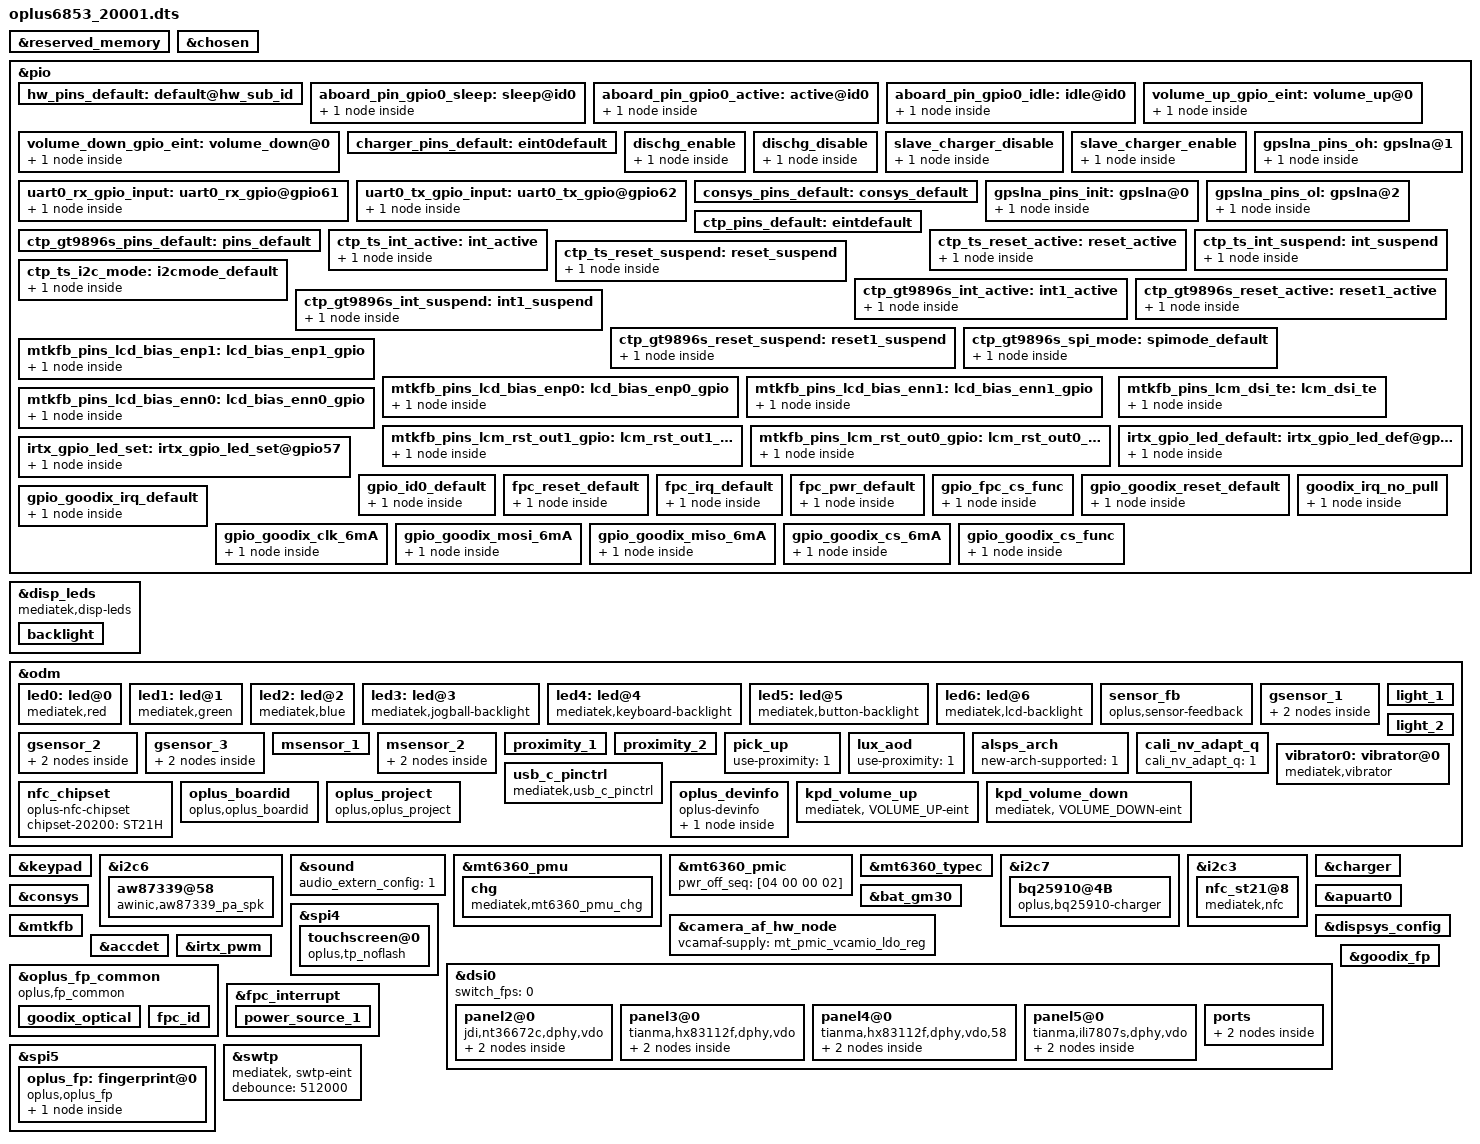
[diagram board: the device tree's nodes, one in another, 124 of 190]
/*
 * Mediatek's mt6853 SoC device tree source
 *
 * Copyright (C) 2016 MediaTek Inc.
 *
 * This program is free software; you can redistribute it and/or modify
 * it under the terms of the GNU General Public License version 2 as
 * published by the Free Software Foundation.
 *
 * This program is distributed in the hope that it will be useful,
 * but WITHOUT ANY WARRANTY; without even the implied warranty of
 * MERCHANTABILITY or FITNESS FOR A PARTICULAR PURPOSE.
 * See http://www.gnu.org/licenses/gpl-2.0.html for more details.
 */
/dts-v1/;
/plugin/;
#include <dt-bindings/interrupt-controller/irq.h>
#include <dt-bindings/interrupt-controller/arm-gic.h>
#include <dt-bindings/pinctrl/mt6853-pinfunc.h>

&reserved_memory {
};

/* chosen */
&chosen {

	atag,videolfb-fb_base_l = <0x7e605000>;
	atag,videolfb-fb_base_h = <0x0>;
	atag,videolfb-islcmfound = <1>;
	atag,videolfb-islcm_inited = <0>;
	atag,videolfb-fps= <6000>;
	atag,videolfb-vramSize= <0x1be0000>;
	atag,videolfb-lcmname=
		"nt35595_fhd_dsi_cmd_truly_nt50358_drv";
};
&pio {
        hw_pins_default:default@hw_sub_id {
        };

        aboard_pin_gpio0_sleep:sleep@id0 {
                pins_cmd_dat {
                        pinmux = <PINMUX_GPIO91__FUNC_GPIO91>;
                        slew-rate = <0>;
                        bias-pull-down;
                        input-enable;
                };
        };

        aboard_pin_gpio0_active:active@id0 {
                pins_cmd_dat {
                        pinmux = <PINMUX_GPIO91__FUNC_GPIO91>;
                        slew-rate = <0>;
                        bias-pull-up;
                        input-enable;
                };
        };

        aboard_pin_gpio0_idle:idle@id0 {
                pins_cmd_dat {
                        pinmux = <PINMUX_GPIO91__FUNC_GPIO91>;
                        slew-rate = <0>;
                        bias-disable;
                        input-enable;
                };
        };
};

&disp_leds {
	compatible = "mediatek,disp-leds";
	backlight {
		label = "lcd-backlight";
		max-brightness = <4095>;
		led-bits = <12>;
		trans-bits = <12>;
		default-state = "on";
	};
};

&odm {
	led0:led@0 {
		compatible = "mediatek,red";
		led_mode = <0>;
		data = <1>;
		pwm_config = <0 0 0 0 0>;
	};
	led1:led@1 {
		compatible = "mediatek,green";
		led_mode = <0>;
		data = <1>;
		pwm_config = <0 0 0 0 0>;
	};
	led2:led@2 {
		compatible = "mediatek,blue";
		led_mode = <0>;
		data = <1>;
		pwm_config = <0 0 0 0 0>;
	};
	led3:led@3 {
		compatible = "mediatek,jogball-backlight";
		led_mode = <0>;
		data = <1>;
		pwm_config = <0 0 0 0 0>;
	};
	led4:led@4 {
		compatible = "mediatek,keyboard-backlight";
		led_mode = <0>;
		data = <1>;
		pwm_config = <0 0 0 0 0>;
	};
	led5:led@5 {
		compatible = "mediatek,button-backlight";
		led_mode = <0>;
		data = <1>;
		pwm_config = <0 0 0 0 0>;
	};
	led6:led@6 {
		compatible = "mediatek,lcd-backlight";
		led_mode = <4>;
		data = <1>;
		pwm_config = <0 1 0 0 0>;
	};

	sensor_fb: sensor_fb {
		compatible = "oplus,sensor-feedback";
	};

	/*
	enum {
		LIS3DH,
		LSM6DS3,
		BMI160,
		LIS2HH12,
		LSM6DSM,
		BMI2XY,
		LSM6DSO,
		ICM4X6XX,
	};
	*/
	gsensor_1: gsensor_1 {
		status = "okay";
		sensor_name = <6>;//LSM6DSO
		i2c_num = <2>;
		i2c_addr = <0>;
		direction = <7>;
		eint_num = <3>;
		para_num = <2>;
		step_count_7_en = <0>;
		config_miso = <0>;
		correct_y_bias = <0>;
		cali_nv_adapt_q_flag = <1>; // just for oplus MTK5G q projects
		gsensor_para_1 {
			match_projects = <20001 20002 20003>;
			direction_adpt = <0 7 0 7 0 7 0 7>;
		};
		gsensor_para_2 {
			match_projects = <20200>;
			direction_adpt = <2 5 4 5 5 5 6 5>;
		};
	};

	gsensor_2: gsensor_2 {
		status = "okay";
		sensor_name = <4>;//LSM6DSM
		i2c_num = <2>;
		i2c_addr = <0>;
		direction = <7>;
		eint_num = <3>;
		para_num = <2>;
		step_count_7_en = <0>;
		config_miso = <0>;
		correct_y_bias = <0>;
		cali_nv_adapt_q_flag = <1>; // just for oplus MTK5G q projects
		gsensor_para_1 {
			match_projects = <20001 20002 20003>;
			direction_adpt = <0 7 0 7 0 7 0 7>;
		};
		gsensor_para_2 {
			match_projects = <20200>;
			direction_adpt = <2 5 4 5 5 5 6 5>;
		};
	};

	gsensor_3: gsensor_3 {
		status = "okay";
		sensor_name = <2>;//BMI160
		i2c_num = <2>;
		i2c_addr = <0>;
		direction = <4>;
		eint_num = <3>;
		step_count_7_en = <1>;
		config_miso = <0>;
		correct_y_bias = <0>;
		para_num = <2>;
		cali_nv_adapt_q_flag = <1>; // just for oplus MTK5G q projects
		gsensor_para_1 {
			match_projects = <20001 20002 20003>;
			direction_adpt = <0 4 0 4 0 4 0 4>;
		};
		gsensor_para_2 {
			match_projects = <20200>;
			direction_adpt = <2 6 4 6 5 6 6 6>;
		};
	};

	/*
	enum {
		AKM09911,
		MMC3530,
		MMC5603,
		MXG4300,
	};
	*/
	msensor_1: msensor_1 {
		status = "okay";
		sensor_name = <0>;//AKM09911
		i2c_num = <0>;
		i2c_addr = <12>;
		direction = <3>;
		eint_num = <0>;
		parameter-number= <18>;
		soft-mag-parameter = <9454 0 5 1 54 1 5 1 10343 0 143 1 54 1 143 1 10231 0>;
	};
	msensor_2: msensor_2 {
		status = "okay";
		sensor_name = <2>;//MMC5603
		i2c_num = <0>;
		i2c_addr = <48>;
		direction = <3>;
		eint_num = <0>;
		parameter-number= <18>;
		//soft-mag-parameter = <9997 0 37 0 243 1 21 0 10654 0 11 0 868 0 516 1 11372 0>;
		para_num = <2>;
		mag_para_1 {
			match_projects = <20001 20002 20003>;
			soft-mag-parameter = <9997 0 37 0 243 1 21 0 10654 0 11 0 868 0 516 1 11372 0>;
		};
		mag_para_2 {
			match_projects = <20200>;
			soft-mag-parameter = <9566 0 2898 0 290 0 801 0 13224 0 159 1 2426 0 1755 1 12524 0>;
		};
	};
	/*
	enum {
		TMD2725,
		APSD9922,
		STK3335,
		STK3331,
		STK2232,
		TCS3701,
		STK32600,
		STK33502,
		MN78911,
	};
	*/
	proximity_1: proximity_1 {
		status = "okay";
		sensor_name = <7>;//STK33502
		i2c_num = <0>;
		i2c_addr = <70>;
		direction = <4>;
		eint_num = <11>;
		low_step = <300>;
		high_step = <400>;
		low_limit = <400>;
		high_limit = <600>;
		dirty_low_step = <100>;
		dirty_high_step = <150>;
		ps_dirty_limit = <1023>;
		ps_ir_limit = <500>;
		ps_adjust_min = <0>;
		ps_adjust_max = <600>;
		sampling_count = <5>;
		step_max = <400>;
		step_min = <100>;
		step_div = <1500>;
		anti_shake_delta = <80>;
		dynamic_cali_max = <2000>;
		raw2offset_radio = <1000>;
		offset_max = <60000>;
		offset_range_min = <0>;
		offset_range_max = <65534>;
		force_cali_limit = <2000>;
		cali_jitter_limit = <30>;
		cal_offset_margin = <3000>;
		sensor-reg = <0x01 0x33 0x03 0x60>; //according to q, we got 100ma & 800us
	};
	proximity_2: proximity_2 {
		status = "okay";
		sensor_name = <8>;//MN78911
		i2c_num = <0>;
		i2c_addr = <0x41>;
		direction = <4>;
		eint_num = <11>;
		low_step = <300>;
		high_step = <400>;
		low_limit = <400>;
		high_limit = <600>;
		dirty_low_step = <100>;
		dirty_high_step = <150>;
		ps_dirty_limit = <1023>;
		ps_ir_limit = <500>;
		ps_adjust_min = <0>;
		ps_adjust_max = <600>;
		sampling_count = <5>;
		step_max = <400>;
		step_min = <110>;
		step_div = <1500>;
		anti_shake_delta = <80>;
		dynamic_cali_max = <2000>;
		raw2offset_radio = <1000>;
		offset_max = <60000>;
		offset_range_min = <0>;
		offset_range_max = <65534>;
		force_cali_limit = <2000>;
		cali_jitter_limit = <30>;
		cal_offset_margin = <3000>;
	};
	light_1: light_1 {
		status = "okay";
		sensor_name = <7>;//STK33502
		i2c_num = <0>;
		i2c_addr = <70>;
		direction = <4>;
		eint_num = <11>;
		als_buffer_length =<4>;
		als_type = <1>;//<1-normal;2-under screen;3-normal needed compensation>
		als_ratio = <110>;
		device_name = "stk33502";
	};
	/* 20001 not using
	als_radio_lcd:als_radio_lcd {
		status = "okay";
		jdi_als_radio = <110>;
		tianma_als_radio = <90>;
	};
	*/
	light_2: light_2 {
		status = "okay";
		sensor_name = <8>;//MN78911
		i2c_num = <0>;
		i2c_addr = <0x41>;
		direction = <4>;
		eint_num = <11>;
		als_buffer_length = <10>;
		als_ratio = <110>;
		als_type = <1>;
		device_name = "mn78911";
	};
	pick_up: pick_up {
		status = "okay";
		use-proximity = <1>;
	};
	lux_aod: lux_aod {
		status = "okay";
		use-proximity = <1>;
	};
	alsps_arch: alsps_arch {
		status = "okay";
		new-arch-supported = <1>;
	};
	cali_nv_adapt_q: cali_nv_adapt_q {
		status = "okay";
		cali_nv_adapt_q = <1>;
	};
	vibrator0:vibrator@0 {
		compatible = "mediatek,vibrator";
		//#ifdef OPLUS_ARCH_EXTENDS
		vib_timer = <30>;
		vib_limit = <0>;
		//#else
		//vib_timer = <25>;
		//vib_limit = <9>;
		//#endif /* OPLUS_ARCH_EXTENDS */
		//#ifdef OPLUS_ARCH_EXTENDS
		vib_vol= <11>;
		//#endif /* OPLUS_ARCH_EXTENDS */
	};
	usb_c_pinctrl:usb_c_pinctrl {
		compatible = "mediatek,usb_c_pinctrl";
	};

//#ifdef OPLUS_FEATURE_CONNFCSOFT
	nfc_chipset {
		compatible = "oplus-nfc-chipset";
		chipset-20200 = "ST21H";
	};
//#endif /* OPLUS_FEATURE_CONNFCSOFT */

	oplus_boardid:oplus_boardid {
		compatible = "oplus,oplus_boardid";
		oplus_boardid,dtsino="20001";//only one u32
		oplus_boardid,pcbmask="0xffff";//all mask 0xffff
	};
	oplus_project:oplus_project {
		compatible = "oplus,oplus_project";
	};
	oplus_devinfo:oplus_devinfo {
		compatible = "oplus-devinfo";
		pinctrl-names = "default", "aboard_gpio0_sleep", "aboard_gpio0_active";
		pinctrl-0 = <&hw_pins_default>;
		pinctrl-1 = <&aboard_pin_gpio0_sleep>;
		pinctrl-2 = <&aboard_pin_gpio0_active>;
		main-sub {
			compatible = "hw-match, main-sub";
			aboard-gpio0 = <&pio 91 0x00>;
			aboard-patterns = <1 1 1 0>;
			/*main board*/
			match-projects = <20001 20002 20003 20200>;
		};
	};
/*OPLUS_FEAUTRE_KEYPAD keypad start*/
	kpd_volume_up:kpd_volume_up {
		compatible = "mediatek, VOLUME_UP-eint";
		interrupt-parent = <&pio>;
		interrupts = <1 IRQ_TYPE_EDGE_FALLING 1 0>;
		debounce = <32000>;
		status = "okay";
	};

	kpd_volume_down:kpd_volume_down {
		compatible = "mediatek, VOLUME_DOWN-eint";
		interrupt-parent = <&pio>;
		interrupts = <80 IRQ_TYPE_EDGE_FALLING 80 0>;
		debounce = <32000>;
		status = "okay";
	};
/*OPLUS_FEAUTRE_KEYPAD keypad end*/
};
/*OPLUS_FEAUTRE_KEYPAD keypad start*/
&keypad {
	keypad,volume-up	= <&pio 1 0x00>;
	keypad,volume-down	= <&pio 80 0x00>;
	pinctrl-names = "volume_up_as_int", "volume_down_as_int";
	pinctrl-0 = <&volume_up_gpio_eint>;
	pinctrl-1 = <&volume_down_gpio_eint>;
	status = "okay";
};
&pio {
	volume_up_gpio_eint:volume_up@0{
		pins_cmd_dat {
			pinmux = <PINMUX_GPIO1__FUNC_GPIO1>;
			slew-rate = <0>;  /*direction 0:in, 1:out*/
			input-enable;
		};
	};

	volume_down_gpio_eint:volume_down@0{
		pins_cmd_dat {
			pinmux = <PINMUX_GPIO80__FUNC_GPIO80>;
			slew-rate = <0>;  /*direction 0:in, 1:out*/
			input-enable;
		};
	};
};
/*OPLUS_FEAUTRE_KEYPAD keypad end*/

/*OPLUS_ARCH_EXTENDS*/
&i2c6 {
    #address-cells = <1>;
    #size-cells = <0>;

    aw87339@58 {
        compatible = "awinic,aw87339_pa_spk";
        reg = <0x58>;
        //reset-gpio = <&tlmm 114 0x01>;
        reset-gpio = <&pio 139 0>;
        status = "okay";
    };
};
/*OPLUS_ARCH_EXTENDS*/
&sound {
	/* this dtsi config for product's special config, AudioHal read ctl 'OPLUS_AUDIO_EXTERN_CONFIG' get the values*
	 * 1st value --> PA type: 0:NXP Pa, 1:Awinic Pa */
	audio_extern_config = <1>;
};
//#endif /* OPLUS_ARCH_EXTENDS */
/* Charging Start */

&mt6360_pmu {
	mt6360,intr_gpio_num = <10>; /* direct defined GPIO num */
	mt6360,intr_gpio = <&pio 10 0x0>;
	disable_lpsd = <1>;
};

&mt6360_pmic {
	pwr_off_seq = [04 00 00 02];
};

&mt6360_typec {
	mt6360pd,intr_gpio_num = <9>; /* direct defined GPIO num */
	mt6360pd,intr_gpio = <&pio 9 0x0>;
	//mt6360pd,pcb_gpio = <&pio 57 0x0>;
	//mt6360pd,pcb_gpio_num = <57>;
};

&mt6360_pmu {
	chg {
		compatible = "mediatek,mt6360_pmu_chg";
		interrupt-parent = <&mt6360_pmu>;
		interrupts = <4 0>, <6 0>, <7 0>, <9 0>,
				<12 0>, <13 0>, <14 0>, <15 0>,
				<27 0>, <29 0>, <30 0>, <32 0>,
				<35 0>, <40 0>, <48 0>, <60 0>,
				<53 0>;
		interrupt-names = "chg_treg_evt", "chg_mivr_evt",
				"pwr_rdy_evt", "chg_batsysuv_evt",
				"chg_vsysuv_evt", "chg_vsysov_evt",
				"chg_vbatov_evt", "chg_vbusov_evt",
				"chg_tmri", "chg_adpbadi",
				"chg_rvpi",  "chg_aiccmeasl",
				"wdtmri", "pumpx_donei",
				"attachi", "chrdet_ext_evt",
				"hvdcp_det";
		io-channels = <&adc 0>, <&adc 1>, <&adc 3>, <&adc 4>,
				<&adc 5>, <&adc 6>, <&adc 8>, <&adc 10>;
		io-channel-names = "USBID", "VBUSDIV5", "VSYS", "VBAT",
				"IBUS", "IBAT", "TEMP_JC", "TS";
		chg_name = "primary_chg";
		ichg = <2000000>;               /* uA */
		aicr = <500000>;                /* uA */
		mivr = <4400000>;               /* uV */
		cv = <4350000>;                 /* uA */
		ieoc = <150000>;                /* uA */
		safety_timer = <12>;            /* hour */
		ircmp_resistor = <25000>;       /* uohm */
		ircmp_vclamp = <32000>;         /* uV */
		en_te = <1>;
		en_wdt = <1>;
		aicc_once = <1>;
		post_aicc = <1>;
		batoc_notify = <0>;
	};
};


&i2c7 {
	bq25910@4B{
		status = "okay";
		compatible = "oplus,bq25910-charger";
		reg = <0x4B>;
		chip-name = "BQ25910";

		pinctrl-names = "slave_charger_disable", "slave_charger_enable";
		pinctrl-0 = <&slave_charger_disable>;
		pinctrl-1 = <&slave_charger_enable>;

		qcom,slave-chg-en-gpio = <&pio 140 0x00>;
	};
};

//#ifdef OPLUS_FEATURE_NFC_BRINGUP
//Add for:NFC ST device
&i2c3 {
       status = "okay";
       nfc_st21@8 {
           compatible ="mediatek,nfc";
           reg = <0x8>;
           gpio-irq-std    = <&pio 5 0x0>;
           gpio-rst-std    = <&pio 11 0x0>;
           gpio-clkreq-std = <&pio 81 0x0>;
       };
};
//#endif /* OPLUS_FEATURE_NFC_BRINGUP */

&charger {
	io-channels =  <&auxadc 3>,<&auxadc 4>,
		<&auxadc 5>;
	io-channel-names = "auxadc3-chargeric_temp","auxadc4-usb_temp_v_l",
		"auxadc5-usb_temp_v_r";

	pinctrl-names = "default", "dischg_enable", "dischg_disable";
	pinctrl-0 = <&charger_pins_default>;
	pinctrl-1 = <&dischg_enable>;
	pinctrl-2 = <&dischg_disable>;

	//for oplus chg framework:
	qcom,input_current_charger_ma = <2000>;
        qcom,input_current_usb_ma = <500>;
        qcom,input_current_cdp_ma = <1500>;
        qcom,input_current_led_ma = <1200>;
        qcom,input_current_led_ma_high = <1000>;
        qcom,input_current_led_ma_warm = <1500>;
        qcom,input_current_led_ma_normal = <2000>;
        qcom,input_current_led_ma_forcmcc = <500>;
        qcom,input_current_camera_ma = <2000>;
        qcom,input_current_calling_ma = <1500>;
        qcom,qc_input_current_charger_ma = <2000>;

	qcom,iterm_disabled = <0>;
	qcom,iterm_ma = <200>;
	qcom,recharge-mv = <100>;

	qcom,batt_capacity_mah = <3945>;

	qcom,removed_bat_decidegc = <190>;  /* < -19C */

	qcom,cold_bat_decidegc = <20>;  /* -2C ~ 0C */
        qcom,temp_cold_vfloat_mv = <3980>;
        qcom,temp_cold_fastchg_current_ma = <300>;

        qcom,little_cold_bat_decidegc = <0>;    /* 0C ~ 5C */
        qcom,temp_little_cold_vfloat_mv = <4385>;
        qcom,temp_little_cold_fastchg_current_ma_high = <550>;
        qcom,temp_little_cold_fastchg_current_ma_low = <550>;
        qcom,temp_little_cold_fastchg_current_ma = <550>;
        qcom,qc_temp_little_cold_fastchg_current_ma_high = <1850>;
        qcom,qc_temp_little_cold_fastchg_current_ma_low = <1100>;

	qcom,cool_bat_decidegc = <50>;  /* 5C ~ 12C */
        qcom,temp_cool_vfloat_mv = <4385>;
        qcom,temp_cool_fastchg_current_ma_high = <1100>;
        qcom,temp_cool_fastchg_current_ma_low = <500>;
        qcom,qc_temp_cool_fastchg_current_ma_high = <3400>;
        qcom,qc_temp_cool_fastchg_current_ma_low = <2600>;

        qcom,little_cool_bat_decidegc = <120>;  /* 12C ~ 16C */
        qcom,temp_little_cool_vfloat_mv = <4385>;
        qcom,temp_little_cool_fastchg_current_ma = <1650>;
        qcom,temp_little_cool_fastchg_current_ma_high = <1650>;
	qcom,temp_little_cool_fastchg_current_ma_low = <1650>;
	qcom,qc_temp_little_cool_fastchg_current_ma = <3400>;

        qcom,normal_bat_decidegc = <160>;       /* 16C ~ 45C */
        qcom,temp_normal_fastchg_current_ma = <2600>;
        qcom,temp_normal_vfloat_mv = <4385>;
        qcom,qc_temp_normal_fastchg_current_ma = <2600>;

        qcom,normal_phase1_bat_decidegc = <160>;       /* 16C ~ 22C */
        qcom,temp_normal_phase1_vfloat_mv = <4385>;
        qcom,temp_normal_phase1_fastchg_current_ma = <3400>;

        qcom,normal_phase2_bat_decidegc = <220>;       /* 22C ~ 34C */
        qcom,temp_normal_phase2_vfloat_mv = <4385>;
        qcom,temp_normal_phase2_fastchg_current_ma_high = <3400>;
        qcom,temp_normal_phase2_fastchg_current_ma_low = <3400>;

        qcom,normal_phase3_bat_decidegc = <340>;       /* 34 ~ 37C */
        qcom,temp_normal_phase3_vfloat_mv = <4385>;
        qcom,temp_normal_phase3_fastchg_current_ma_high = <3100>;
        qcom,temp_normal_phase3_fastchg_current_ma_low = <3100>;

        qcom,normal_phase4_bat_decidegc = <370>;       /* 37C ~ 40C */
        qcom,temp_normal_phase4_vfloat_mv = <4385>;
        qcom,temp_normal_phase4_fastchg_current_ma_high = <2300>;
        qcom,temp_normal_phase4_fastchg_current_ma_low = <2300>;

        qcom,normal_phase5_bat_decidegc = <400>;       /* 40C ~ 42C */
        qcom,temp_normal_phase5_vfloat_mv = <4385>;
        qcom,temp_normal_phase5_fastchg_current_ma = <2000>;

        qcom,normal_phase6_bat_decidegc = <420>;       /* 42C ~ 45C */
        qcom,temp_normal_phase6_vfloat_mv = <4385>;
        qcom,temp_normal_phase6_fastchg_current_ma = <1100>;


        qcom,warm_bat_decidegc = <450>;         /* 45C ~ 53C */ /*8pin Bat Vooc project need add 3 degree C*/
        qcom,temp_warm_vfloat_mv = <4130>;
        qcom,temp_warm_fastchg_current_ma = <1100>;
        qcom,temp_warm_fastchg_current_ma_led_on = <500>;
        qcom,qc_temp_warm_fastchg_current_ma = <1100>;

	qcom,hot_bat_decidegc = <530>;  /* > 53C */

	qcom,non_standard_vfloat_mv = <3980>;
	qcom,non_standard_fastchg_current_ma = <512>;

	qcom,short_c_bat_cv_mv = <4330>;
	qcom,short_c_bat_vfloat_mv = <3800>;
	qcom,short_c_bat_fastchg_current_ma = <512>;
	qcom,short_c_bat_vfloat_sw_limit = <3750>;

	qcom,cold_vfloat_sw_limit = <3930>;
	qcom,little_cold_vfloat_sw_limit = <4320>;
	qcom,cool_vfloat_sw_limit = <4320>;
	qcom,little_cool_vfloat_sw_limit = <4320>;
	qcom,normal_vfloat_sw_limit = <4320>;
	qcom,warm_vfloat_sw_limit = <4030>;
	qcom,non_standard_vfloat_sw_limit = <3930>;

	qcom,max_chg_time_sec = <56808>;
	qcom,charger_hv_thr = <10000>;
	qcom,charger_recv_thr = <9700>;
	qcom,charger_lv_thr = <3400>;
	qcom,vbatt_full_thr = <4400>;
	qcom,vbatt_hv_thr = <4500>;

	qcom,vfloat_step_mv = <16>;
	qcom,non_standard_vfloat_over_sw_limit = <3980>;
	qcom,cold_vfloat_over_sw_limit = <3980>;
	qcom,little_cold_vfloat_over_sw_limit = <4390>;
	qcom,cool_vfloat_over_sw_limit = <4390>;
	qcom,little_cool_vfloat_over_sw_limit = <4390>;
	qcom,normal_vfloat_over_sw_limit = <4390>;
	qcom,warm_vfloat_over_sw_limit = <4080>;

	qcom,vbatt_power_off = <3300>;
	qcom,vbatt_soc_1 = <3410>;
	//qcom,vooc_project = <1>;
	qcom,vbatt_num = <1>;

	qcom,normal_vterm_hw_inc = <18>;
	qcom,non_normal_vterm_hw_inc = <18>;

	qcom,overchg_normal_fastchg_ma = <700>;/*16C~35c*/
	qcom,overchg_temp_warm_decidegc = <350>;
	qcom,overchg_warm_fastchg_ma = <750>;/*35C~40c*/
	qcom,overchg_temp_high_decidegc = <400>;

	qcom,overchg_normal_vfloat_sw_limit = <4450>;
	qcom,overchg_temp_normal_vfloat_mv = <4500>;
	qcom,overchg_normal_vfloat_over_sw_limit = <4500>;

	qcom,default_iterm_ma = <200>;
	qcom,default_temp_normal_fastchg_current_ma = <2000>;
	qcom,default_normal_vfloat_sw_limit = <4320>;
	qcom,default_temp_normal_vfloat_mv = <4385>;
	qcom,default_normal_vfloat_over_sw_limit = <4390>;

	//for control:
	//qcom,suspend_after_full;
	qcom,check_batt_full_by_sw;
	qcom,external_gauge;
	qcom,chg_ctrl_by_calling;
	qcom,chg_ctrl_by_lcd;
	qcom,chg_ctrl_by_camera;
	qcom,support_ntc_01c_precision;
	qcom,sw_vfloat_over_protect_enable;

	//for PD9V or QC9V
	qcom,vbatt_pdqc_to_5v_thr = <3400>;
	qcom,dual_charger_support = <1>;
	qcom,slave_pct = <30>;
	qcom,slave_chg_enable_ma = <2500>;
	qcom,slave_chg_disable_ma = <2300>;
	qcom,old_smart_charge_standard;

	//for step charger
	qcom,step1_time = <600>;		/*10min*/
	qcom,step1_current_ma = <3400>;		/*3400ma*/
	qcom,step2_time = <600>;		/*10min*/
	qcom,step2_current_ma = <3100>;		/*3100ma*/
	qcom,step3_current_ma = <2700>;		/*2700ma*/

	//GPIO config:
	qcom,dischg-gpio = <&pio 128 0x00>;
};
&bat_gm30 {
	FUELGAGUE_APPLY = <(1)>;
	RBAT_PULL_UP_R = <(16000)>;
	io-channels = <&auxadc 6>;
	io-channel-names = "auxadc6-batt_id_v";
};

&pio {
	charger_pins_default: eint0default {
	};

	dischg_enable: dischg_enable {
		pins_cmd_dat {
			pinmux = <PINMUX_GPIO128__FUNC_GPIO128>;
			slew-rate = <1>;//0:input direction 1:output direction
			//bias-pull-up = <00>;
			output-high;
		};
	};

	dischg_disable: dischg_disable {
		pins_cmd_dat {
			pinmux = <PINMUX_GPIO128__FUNC_GPIO128>;
			slew-rate = <1>;
			//bias-pull-down = <00>;
			output-low;
		};
	};

		slave_charger_disable: slave_charger_disable {
                pins_cmd_dat {
                        pinmux = <PINMUX_GPIO140__FUNC_GPIO140>;
                        slew-rate = <1>;//0:input direction 1:output direction
                        bias-pull-up = <00>;
                        output-low;
                };
        };

        slave_charger_enable: slave_charger_enable {
                pins_cmd_dat {
                        pinmux = <PINMUX_GPIO140__FUNC_GPIO140>;
                        slew-rate = <1>;
                        bias-pull-down = <00>;
                        output-high;
                };
        };

};

//#ifdef OPLUS_ARCH_EXTENDS
&apuart0 {
	pinctrl-names = "uart0_rx_gpio",
			"uart0_tx_gpio";
	pinctrl-0 = <&uart0_rx_gpio_input>;
	pinctrl-1 = <&uart0_tx_gpio_input>;
	status = "okay";
};

&pio {
	uart0_rx_gpio_input:uart0_rx_gpio@gpio61 {
		pins_cmd_dat {
			pinmux = <PINMUX_GPIO61__FUNC_GPIO61>;
			input-enable;
			slew-rate = <0>;
			bias-disable;
		};
	};
	uart0_tx_gpio_input:uart0_tx_gpio@gpio62 {
		pins_cmd_dat {
			pinmux = <PINMUX_GPIO62__FUNC_GPIO62>;
			input-enable;
			slew-rate = <0>;
			bias-disable;
		};
	};
};

//#endif /* OPLUS_ARCH_EXTENDS */

/* Charging end  */
/* USB SWITCH GPIO start */
/*&pio {
	usb_default: usb_default {
	};

	gpio_redriver_c1_init: c1_init {
		pins_cmd_dat {
			pinmux = <PINMUX_GPIO41__FUNC_GPIO41>;
			slew-rate = <1>;
			output-low;
		};
	};

	gpio_redriver_c1_low: c1_low {
		pins_cmd_dat {
			pinmux = <PINMUX_GPIO41__FUNC_GPIO41>;
			slew-rate = <1>;
			output-low;
		};
	};

	gpio_redriver_c1_hiz: c1_highz {
		pins_cmd_dat {
			pinmux = <PINMUX_GPIO41__FUNC_GPIO41>;
			slew-rate= <0>;
			bias-disable;
		};
	};

	gpio_redriver_c1_high: c1_high {
		pins_cmd_dat {
			pinmux = <PINMUX_GPIO41__FUNC_GPIO41>;
			slew-rate = <1>;
			output-high;
		};
	};

	gpio_redriver_c2_init: c2_init {
		pins_cmd_dat {
			pinmux = <PINMUX_GPIO40__FUNC_GPIO40>;
			slew-rate = <1>;
			output-low;
		};
	};

	gpio_redriver_c2_low: c2_low {
		pins_cmd_dat {
			pinmux = <PINMUX_GPIO40__FUNC_GPIO40>;
			slew-rate = <1>;
			output-low;
		};
	};

	gpio_redriver_c2_hiz: c2_highz {
		pins_cmd_dat {
			pinmux = <PINMUX_GPIO40__FUNC_GPIO40>;
			slew-rate= <0>;
			bias-disable;
		};
	};

	gpio_redriver_c2_high: c2_high {
		pins_cmd_dat {
			pinmux = <PINMUX_GPIO40__FUNC_GPIO40>;
			slew-rate = <1>;
			output-high;
		};
	};

	gpio_u3_switch_sel1: u3_sw_sel1 {
		pins_cmd_dat {
			pinmux = <PINMUX_GPIO11__FUNC_GPIO11>;
			slew-rate = <1>;
			output-low;
		};
	};

	gpio_u3_switch_sel2: u3_sw_sel2 {
		pins_cmd_dat {
			pinmux = <PINMUX_GPIO11__FUNC_GPIO11>;
			slew-rate = <1>;
			output-high;
		};
	};

	gpio_u3_switch_enable: u3_sw_en {
	};

	gpio_u3_switch_disable: u3_sw_dis {
	};
};

&usb_c_pinctrl {
	pinctrl-names = "usb_default",
		"redrv_c1_init",
		"redrv_c1_low",
		"redrv_c1_hiz",
		"redrv_c1_high",
		"redrv_c2_init",
		"redrv_c2_low",
		"redrv_c2_hiz",
		"redrv_c2_high",
		"switch_sel1",
		"switch_sel2",
		"switch_enable",
		"switch_disable";

	pinctrl-0 = <&usb_default>;
	pinctrl-1 = <&gpio_redriver_c1_init>;
	pinctrl-2 = <&gpio_redriver_c1_low>;
	pinctrl-3 = <&gpio_redriver_c1_hiz>;
	pinctrl-4 = <&gpio_redriver_c1_high>;
	pinctrl-5 = <&gpio_redriver_c2_init>;
	pinctrl-6 = <&gpio_redriver_c2_low>;
	pinctrl-7 = <&gpio_redriver_c2_hiz>;
	pinctrl-8 = <&gpio_redriver_c2_high>;
	pinctrl-9 = <&gpio_u3_switch_sel1>;
	pinctrl-10 = <&gpio_u3_switch_sel2>;
	pinctrl-11 = <&gpio_u3_switch_enable>;
	pinctrl-12 = <&gpio_u3_switch_disable>;
	status = "okay";

	usb_switch-data {
		en_pin_num = <0>;
		en_pin_val = <0>;
		sel_pin_num = <11>;
		sel_pin_val = <1>;
		c1_pin_num = <41>;
		c1_pin_val = <2>;
		c2_pin_num = <40>;
		c2_pin_val = <1>;
	};
};*/
/* USB SWITCH GPIO end */


/* CONSYS GPIO standardization */
&pio {
	consys_pins_default: consys_default {
	};
	gpslna_pins_init: gpslna@0 {
		pins_cmd_dat {
			pinmux = <PINMUX_GPIO87__FUNC_GPIO87>;
			output-low;
		};
	};
	gpslna_pins_oh: gpslna@1 {
		pins_cmd_dat {
			pinmux = <PINMUX_GPIO87__FUNC_GPS_L1_ELNA_EN>;
		};
	};
	gpslna_pins_ol: gpslna@2 {
		pins_cmd_dat {
			pinmux = <PINMUX_GPIO87__FUNC_GPIO87>;
			output-low;
		};
	};
};

&consys {
	pinctrl-names = "default", "gps_lna_state_init",
		"gps_lna_state_oh", "gps_lna_state_ol";
	pinctrl-0 = <&consys_pins_default>;
	pinctrl-1 = <&gpslna_pins_init>;
	pinctrl-2 = <&gpslna_pins_oh>;
	pinctrl-3 = <&gpslna_pins_ol>;
	status = "okay";
};
/* CONSYS end */

/*#ifdef OPLUS_FEATURE_TP_BASIC*/
/* TOUCH start */
&spi4 {
	status = "okay";

	touchscreen@0 {
		compatible = "oplus,tp_noflash";
		reg = <0>; //Same as CS ID
		chip-name = "OPLUS_TP_NOFLASH";
		status = "ok";

		spi-max-frequency = <9600000>;
		interrupt-parent = <&pio>;
		interrupts = <14 IRQ_TYPE_EDGE_FALLING 14 0>;
		irq-gpio = <&pio 14 0x2002>;
		reset-gpio = <&pio 43 0>;

		platform_support_project = <20001 20002 20003 20200>;
		platform_support_project_dir = <20001 20001 20001 20001 >;
		platform_support_project_commandline = "default_commandline","default_commandline","default_commandline","default_commandline";

		touchpanel,max-num-support = <10>;
		touchpanel,tx-rx-num = <16 36>;
		touchpanel,panel-coords = <1080 2400>;
		touchpanel,display-coords = <1080 2400>;
		touchpanel,touchmajor-limit = <0 54>;

		pinctrl-names = "default", "suspend";
		pinctrl-0 = <&ctp_gt9896s_int_active &ctp_gt9896s_reset_active &ctp_gt9896s_spi_mode>;
		pinctrl-1 = <&ctp_gt9896s_int_suspend &ctp_gt9896s_reset_suspend>;

		incell_screen;
		fw_edge_limit_support;
		black_gesture_support;
		charger_pump_support;
		headset_pump_support;
		esd_handle_support;
		black_gesture_test_support;
		game_switch_support;
		noflash_support;
		lcd_trigger_load_tp_fw_support;
		smart_gesture_support;
		pressure_report_support;
		fw_update_app_support;
		health_monitor_v2_support;
		//fw_update_in_probe_with_headfile;

		touchpanel,button-type = <4>;
	};
};
/*#endif OPLUS_FEATURE_TP_BASIC*/


&pio {
	ctp_pins_default: eintdefault {
	};
	ctp_gt9896s_pins_default: pins_default {
	};
	ctp_ts_int_active: int_active {
		pins_cmd_dat {
			pinmux = <PINMUX_GPIO14__FUNC_GPIO14>;
			slew-rate = <0>;
			bias-pull-up = <11>;
		};
	};
	ctp_ts_reset_active: reset_active {
		pins_cmd_dat {
			pinmux = <PINMUX_GPIO43__FUNC_GPIO43>;
			slew-rate = <1>;
			output-high;
		};
	};
	ctp_ts_int_suspend: int_suspend {
		pins_cmd_dat {
			pinmux = <PINMUX_GPIO14__FUNC_GPIO14>;
			slew-rate = <1>;
			output-low;
		};
	};
	ctp_ts_reset_suspend: reset_suspend {
		pins_cmd_dat {
			pinmux = <PINMUX_GPIO43__FUNC_GPIO43>;
			slew-rate = <1>;
			output-low;
		};
	};
	ctp_ts_i2c_mode: i2cmode_default {
		pins_cmd_dat {
			pinmux = <PINMUX_GPIO97__FUNC_SCL0>,
				<PINMUX_GPIO98__FUNC_SDA0>;
		};
	};
	ctp_gt9896s_int_active: int1_active {
		pins_cmd_dat {
			pinmux = <PINMUX_GPIO14__FUNC_GPIO14>;
			slew-rate = <0>;
			bias-pull-up = <11>;
		};
	};
	ctp_gt9896s_reset_active: reset1_active {
		pins_cmd_dat {
			pinmux = <PINMUX_GPIO43__FUNC_GPIO43>;
			slew-rate = <1>;
			output-high;
		};
	};
	ctp_gt9896s_int_suspend: int1_suspend {
		pins_cmd_dat {
			pinmux = <PINMUX_GPIO14__FUNC_GPIO14>;
			slew-rate = <1>;
			output-low;
		};
	};
	ctp_gt9896s_reset_suspend: reset1_suspend {
		pins_cmd_dat {
			pinmux = <PINMUX_GPIO43__FUNC_GPIO43>;
			slew-rate = <1>;
			output-low;
		};
	};
	ctp_gt9896s_spi_mode: spimode_default {
		pins_cmd_dat {
			pinmux = <PINMUX_GPIO12__FUNC_SPI4_MI>,
				<PINMUX_GPIO13__FUNC_SPI4_MO>,
				<PINMUX_GPIO97__FUNC_SPI4_CLK>,
				<PINMUX_GPIO98__FUNC_SPI4_CSB>;
			drive-strength = <4>;
		};
	};
};
/* TOUCH end */

//#include "mediatek/cust_mt6853_touch_1080x1920.dtsi"
#include "mediatek/cust_mt6853_camera_20001.dtsi"
#include <oplus6853_20001/cust.dtsi>
/* DISPSYS GPIO standardization */

#ifndef CONFIG_FPGA_EARLY_PORTING
&pio {
	mtkfb_pins_lcd_bias_enp1: lcd_bias_enp1_gpio {
		pins_cmd_dat {
			pinmux = <PINMUX_GPIO137__FUNC_GPIO137>;
			slew-rate = <1>;
			output-high;
		};
	};

	mtkfb_pins_lcd_bias_enp0: lcd_bias_enp0_gpio {
		pins_cmd_dat {
			pinmux = <PINMUX_GPIO137__FUNC_GPIO137>;
			slew-rate = <1>;
			output-low;
		};
	};

	mtkfb_pins_lcd_bias_enn1: lcd_bias_enn1_gpio {
		pins_cmd_dat {
			pinmux = <PINMUX_GPIO138__FUNC_GPIO138>;
			slew-rate = <1>;
			output-high;
		};
	};

	mtkfb_pins_lcd_bias_enn0: lcd_bias_enn0_gpio {
		pins_cmd_dat {
			pinmux = <PINMUX_GPIO138__FUNC_GPIO138>;
			slew-rate = <1>;
			output-low;
		};
	};

	mtkfb_pins_lcm_rst_out1_gpio: lcm_rst_out1_gpio {
		pins_cmd_dat {
			pinmux = <PINMUX_GPIO86__FUNC_GPIO86>;
			slew-rate = <1>;
			output-high;
		};
	};

	mtkfb_pins_lcm_rst_out0_gpio: lcm_rst_out0_gpio {
		pins_cmd_dat {
			pinmux = <PINMUX_GPIO86__FUNC_GPIO86>;
			slew-rate = <1>;
			output-low;
		};
	};
	mtkfb_pins_lcm_dsi_te: lcm_dsi_te {
		pins_cmd_dat {
			pinmux = <PINMUX_GPIO84__FUNC_DSI_TE>;
		};
	};
};

&camera_af_hw_node {
	vcamaf-supply = <&mt_pmic_vcamio_ldo_reg>;
	status = "okay";
};

&mtkfb {
	pinctrl-names = "lcd_bias_enp1_gpio", "lcd_bias_enp0_gpio",
		"lcd_bias_enn1_gpio", "lcd_bias_enn0_gpio",
		"lcm_rst_out1_gpio", "lcm_rst_out0_gpio",
		"mode_te_te";
	pinctrl-0 = <&mtkfb_pins_lcd_bias_enp1>;
	pinctrl-1 = <&mtkfb_pins_lcd_bias_enp0>;
	pinctrl-2 = <&mtkfb_pins_lcd_bias_enn1>;
	pinctrl-3 = <&mtkfb_pins_lcd_bias_enn0>;
	pinctrl-4 = <&mtkfb_pins_lcm_rst_out1_gpio>;
	pinctrl-5 = <&mtkfb_pins_lcm_rst_out0_gpio>;
	pinctrl-6 = <&mtkfb_pins_lcm_dsi_te>;
	status = "okay";
};
&dispsys_config {
	pinctrl-names =
		"lcm_rst_out1_gpio", "lcm_rst_out0_gpio",
		"mode_te_te";
	pinctrl-0 = <&mtkfb_pins_lcm_rst_out1_gpio>;
	pinctrl-1 = <&mtkfb_pins_lcm_rst_out0_gpio>;
	pinctrl-2 = <&mtkfb_pins_lcm_dsi_te>;
	status = "okay";

	helper-value = <0>, /*MTK_DRM_OPT_STAGE*/
		<1>, /*MTK_DRM_OPT_USE_CMDQ*/
		<1>, /*MTK_DRM_OPT_USE_M4U*/
		<0>, /*MTK_DRM_OPT_SODI_SUPPORT*/
		<1>, /*MTK_DRM_OPT_IDLE_MGR*/
		<0>, /*MTK_DRM_OPT_IDLEMGR_SWTCH_DECOUPLE*/
		<1>, /*MTK_DRM_OPT_IDLEMGR_BY_REPAINT*/
		<0>, /*MTK_DRM_OPT_IDLEMGR_ENTER_ULPS*/
		<0>, /*MTK_DRM_OPT_IDLEMGR_KEEP_LP11*/
		<0>, /*MTK_DRM_OPT_DYNAMIC_RDMA_GOLDEN_SETTING*/
		<1>, /*MTK_DRM_OPT_IDLEMGR_DISABLE_ROUTINE_IRQ*/
		<0>, /*MTK_DRM_OPT_MET_LOG*/
		<1>, /*MTK_DRM_OPT_USE_PQ*/
		<1>, /*MTK_DRM_OPT_ESD_CHECK_RECOVERY*/
		<1>, /*MTK_DRM_OPT_ESD_CHECK_SWITCH*/
		<1>, /*MTK_DRM_OPT_PRESENT_FENCE*/
		<0>, /*MTK_DRM_OPT_RDMA_UNDERFLOW_AEE*/
		<1>, /*MTK_DRM_OPT_DSI_UNDERRUN_AEE*/
		<1>, /*MTK_DRM_OPT_HRT*/
		<1>, /*MTK_DRM_OPT_HRT_MODE*/
		<0>, /*MTK_DRM_OPT_DELAYED_TRIGGER*/
		<1>, /*MTK_DRM_OPT_OVL_EXT_LAYER*/
		<0>, /*MTK_DRM_OPT_AOD*/
		<1>, /*MTK_DRM_OPT_RPO*/
		<0>, /*MTK_DRM_OPT_DUAL_PIPE*/
		<0>, /*MTK_DRM_OPT_DC_BY_HRT*/
		<0>, /*MTK_DRM_OPT_OVL_WCG*/
		<0>, /*MTK_DRM_OPT_OVL_SBCH*/
		<1>, /*MTK_DRM_OPT_COMMIT_NO_WAIT_VBLANK*/
		<0>, /*MTK_DRM_OPT_MET*/
		<0>, /*MTK_DRM_OPT_REG_PARSER_RAW_DUMP*/
		<0>, /*MTK_DRM_OPT_VP_PQ*/
		<0>, /*MTK_DRM_OPT_GAME_PQ*/
		<0>, /*MTK_DRM_OPT_MMPATH*/
		<0>, /*MTK_DRM_OPT_HBM*/
		<1>, /*MTK_DRM_OPT_VDS_PATH_SWITCH*/
		<0>, /*MTK_DRM_OPT_LAYER_REC*/
		<1>, /*MTK_DRM_OPT_CLEAR_LAYER*/
		<1>, /*MTK_DRM_OPT_LFR*/
		<0>; /*MTK_DRM_OPT_SF_PF*/
};
&dsi0 {
	status = "okay";
	#address-cells = <1>;
	#size-cells = <0>;
	switch_fps = <0>;
	panel2@0 {
		compatible = "jdi,nt36672c,dphy,vdo";
		reg = <0>;
		pm-enable-gpios = <&pio 41 0>;
		reset-gpios = <&pio 86 0>;
 		bias-gpios = <&pio 137 0>,
 			<&pio 138 0>;
		pinctrl-names = "default";
		port {
			panel_in2: endpoint {
				remote-endpoint = <&dsi_out>;
			};
		};
	};
	panel3@0 {
		compatible = "tianma,hx83112f,dphy,vdo";
		reg = <1>;
		pm-enable-gpios = <&pio 41 0>;
		reset-gpios = <&pio 86 0>;
		bias-gpios = <&pio 137 0>,
			<&pio 138 0>;
		pinctrl-names = "default";
		port {
			panel_in3: endpoint {
				remote-endpoint = <&dsi_out>;
			};
		};
	};
	panel4@0 {
		compatible = "tianma,hx83112f,dphy,vdo,58";
		reg = <2>;
		pm-enable-gpios = <&pio 41 0>;
		reset-gpios = <&pio 86 0>;
		bias-gpios = <&pio 137 0>,
			<&pio 138 0>;
		pinctrl-names = "default";
		port {
			panel_in4: endpoint {
				remote-endpoint = <&dsi_out>;
			};
		};
	};
	panel5@0 {
		compatible = "tianma,ili7807s,dphy,vdo";
		reg = <3>;
		pm-enable-gpios = <&pio 41 0>;
		reset-gpios = <&pio 86 0>;
		bias-gpios = <&pio 137 0>,
			<&pio 138 0>;
		pinctrl-names = "default";
		port {
			panel_in5: endpoint {
				remote-endpoint = <&dsi_out>;
			};
		};
	};
	ports {
		port {
			dsi_out: endpoint {
				remote-endpoint = <&panel_in2>;
			};
		};
	};
};

/* accdet start */
&accdet {
	/* accdet micbias voltage: 0x09:2.85v 0x08:2.8v 0x07,
	 * 2.7v;0x05,2.5v;0x02,1.9v
	 */
	accdet-mic-vol = <8>;
	/* accdet pwm_width, pwm_thresh, fall_delay, rise_delay
	 * debounce0, debounce1, debounce3, debounce4
	 * eint pwm_width, eint pwm_thresh
	 * eint deb(debounce0, debounce1, debounce2, debounce3), inv_debounce
	 */

        //#ifdef OPLUS_ARCH_EXTENDS
        headset-mode-setting = <0x500 0x500 1 0x1f0
                                0x2000 0x800 0x2000 0x44
                                0x0 0x7
                                0x5 0x9 0x9 0xd 0xe>;
        //#else /* OPLUS_ARCH_EXTENDS */
        /*headset-mode-setting = <0x500 0x500 1 0x1f0
         *                      0x800 0x800 0x20 0x44
         *                      0x4 0x1
         *                      0x5 0x3 0x3 0x5 0xe>;
         */
         //#endif /* OPLUS_ARCH_EXTENDS */

	accdet-plugout-debounce = <1>;
	/*1:ACC mode, 2:low cost without in bias, 6:low cost with in bias*/
	accdet-mic-mode = <2>;
	/*0--MD_MAX--UP_MAX--DW_MAX*/
	//#ifdef OPLUS_ARCH_EXTENDS
	headset-three-key-threshold = <0 82 170 306>;
	//#else /* OPLUS_ARCH_EXTENDS */
	//headset-three-key-threshold = <0 80 220 400>;
	//#endif /* OPLUS_ARCH_EXTENDS */
	headset-three-key-threshold-CDD = <0 121 192 600>;
	/*0--MD_MAX--VOICE_MAX--UP_MAX--DW_MAX*/
	headset-four-key-threshold = <0 58 121 192 400>;

        //#ifdef OPLUS_ARCH_EXTENDS
	/* moisture HW mode config start. Enable moisture detection or not
	 * default use HW mode for moisture detection
	 */
	moisture_detect_enable = <1>;
        //#endif /* OPLUS_ARCH_EXTENDS */
	/* select VTH to 2v and 500k, use internal resitance */
	eint_use_ext_res = <0>;
        //#ifdef OPLUS_ARCH_EXTENDS
	/* enable eint detection mode, if moisture detection enable
	 * eint_detect_mode = moisture_detect_mode;otherwise, select
	 * eint_detect_mode = 4 as DEFAULT
	 */
	eint_detect_mode = <5>;
	/* enable moisture detection mode, if moisture detection enable
	 * eint_detect_mode = moisture_detect_mode
	 */
	moisture_detect_mode = <5>;
	/* select 0: 2.8V; 1: 2.4V; 2: 2V; 3: VTH=MVTH(VTH2) */
	moisture_comp_vth = <2>;
	/* vref2 voltage for different water impedance */
	moisture_comp_vref2 = <2>;
	/* moisture HW mode config end */

	/* moisture SW mode config start, use external resister or not.
	 * DEFAULT NOT NEED
	 */
	moisture_use_ext_res = <0>;
	/* moisture external resister ohm, SW mode by auxadc */
	moisture-external-r = <2000000>;
	/* moisture internal resister ohm, SW mode by auxadc */
	moisture-internal-r = <47000>;
	/* moisture of water resister ohm, SW mode by auxadc*/
	moisture-water-r = <10000>;
	/* moisture SW mode config end */
        //#endif /* OPLUS_ARCH_EXTENDS */
	status = "okay";
};
/* accdet end */

/* IRTX GPIO Start */
&irtx_pwm {
	pinctrl-names = "irtx_gpio_led_default", "irtx_gpio_led_set";
	pinctrl-0 = <&irtx_gpio_led_default>;
	pinctrl-1 = <&irtx_gpio_led_set>;
	status = "okay";
};
&pio {
	/* IRTX GPIO Settings -Start */
	/* default: GPIO0, output, high */
	irtx_gpio_led_default:irtx_gpio_led_def@gpio57 {
		pins_cmd_dat {
			pinmux = <PINMUX_GPIO57__FUNC_GPIO57>;
			slew-rate = <1>;
			bias-disable;
			output-low;
			input-schmitt-enable = <0>;
		};
	};

	irtx_gpio_led_set:irtx_gpio_led_set@gpio57 {
		pins_cmd_dat {
			pinmux = <PINMUX_GPIO57__FUNC_PWM_3>;
			slew-rate = <1>;
			output-high;
		};
	};
}; /* IRTX GPIO Settings -End */

#endif

/* FINGERPRINT start */
//ifdef OPLUS_FEATURE_FINGERPRINT
&oplus_fp_common {
    compatible = "oplus,fp_common"; //Manufacture, and Model
    oplus,fp_gpio_num = <1>;
    oplus,fp_gpio_0 = <&pio 41 0x0>;
    pinctrl-names = "default";
    pinctrl-0 = <&gpio_id0_default>;
    goodix_optical {
        oplus,fp-id = <1>; /* fp id mapping table */
        vendor-chip = <16>; /* please refer to the struct fp_vendor_t in oplus_fp_commmon.n */
        eng-menu = "-1,-1"; /* represents SNR, inclination test item in engineer menu, and 0/1 means off/on */
        chip-name = "G_3626";  /* /proc/fp_id, will be displayed in engineer menu  */
    };
    fpc_id {
        oplus,fp-id = <0>; /* fp id mapping table */
        vendor-chip = <17>; /* please refer to the struct fp_vendor_t in oplus_fp_commmon.n */
        eng-menu = "-1,-1"; /* represents SNR, inclination test item in engineer menu, and 0/1 means off/on */
        chip-name = "F_1541";  /* /proc/fp_id, will be displayed in engineer menu  */
        };
};

&pio{
	gpio_id0_default: gpio_id0_default {
		pins_cmd_dat {
			pinmux = <PINMUX_GPIO41__FUNC_GPIO41>;
			input;
			bias-disable;
			input-enable;
		};
	};
};

/* fpc GPIO standardization */

&fpc_interrupt {
	pinctrl-names = "default", "fpc_cs_func";
	fpc,irq-gpio    = <&pio 7 0x00>;
	fpc,reset-gpio  = <&pio 6 0x00>;
	fpc,vdd-en = <&pio 131 0x00>;
	fpc,gpio_cs = <&pio 29 0x00>;
	fpc,use_gpio_power_enable = <1>;
	pinctrl-0 = <&fpc_reset_default>,<&fpc_irq_default>,<&fpc_pwr_default>;
	pinctrl-1 = <&gpio_fpc_cs_func>;
	pw_en_gpio = <&pio 131 0x00>;
	status = "okay";
	power_source_1 {
		power-mode = <2>;
		power-name = "pw_en_gpio";
		poweron-level = <0>;
		delay-time = <0>;
	};
};

&pio {
	fpc_reset_default: fpc_reset_default {
		pins_cmd_dat {
			pinmux = <PINMUX_GPIO6__FUNC_GPIO6>;
			bias-disable;
			output-low;
		};
	};
	fpc_irq_default: fpc_irq_default {
		pins_cmd_dat {
			pinmux = <PINMUX_GPIO7__FUNC_GPIO7>;
			bias-pull-up;
		};
	};
	fpc_pwr_default: fpc_pwr_default {
		pins_cmd_dat {
			pinmux = <PINMUX_GPIO131__FUNC_GPIO131>;
			bias-disable;
			output-low;
		};
	};
	gpio_fpc_cs_func: gpio_fpc_cs_func {
		pins_cmd_dat {
			pinmux = <PINMUX_GPIO29__FUNC_SPI5_CSB>;
			drive-strength = <3>;
		};
	};
};

&goodix_fp {
	goodix,gpio_irq = <&pio 7 0x00>;
	goodix,gpio_reset = <&pio 6 0x00>;
	goodix,gpio_cs = <&pio 29 0x00>;
	pinctrl-names = "default", "goodix_irq_no_pull", "gf_cs_func";
	pinctrl-0 = <&gpio_goodix_irq_default>, <&gpio_goodix_reset_default>;
	pinctrl-1 = <&goodix_irq_no_pull>, <&gpio_goodix_clk_6mA>, <&gpio_goodix_mosi_6mA>, <&gpio_goodix_miso_6mA>, <&gpio_goodix_cs_6mA>;
	pinctrl-2 = <&gpio_goodix_cs_func>;
	status = "okay";
};

&spi5 {
#address-cells = <1>;
#size-cells = <0>;
status = "okay";
oplus_fp: fingerprint@0 {
		compatible = "oplus,oplus_fp";
		reg = <0>;
		spi-max-frequency = <8000000>;
		spi-id = <5>;
		spi-irq = <39>;
		spi-reg = <11019000>;
		dvdd-supply = <&mt_pmic_vfp_ldo_reg>;
		dvdd-config = <3000000 3000000 150000>;
		power-num = <2>;
		status = "okay";
		power_source_1 {
			power-mode = <1>;
			power-name = "dvdd";
			power-config = "dvdd-config";
			delay-time = <0>;
		};
	};
};
/* 1 = ldo power, refer to oplus_fp_common.h*/
&pio{
gpio_goodix_reset_default: gpio_goodix_reset_default {
				pins_cmd_dat {
					pinmux = <PINMUX_GPIO6__FUNC_GPIO6>;
					output-low;
				};
			};
gpio_goodix_irq_default: gpio_goodix_irq_default {
				pins_cmd_dat {
					pinmux = <PINMUX_GPIO7__FUNC_GPIO7>;
					bias-pull-down;
				};
			};
goodix_irq_no_pull: goodix_irq_no_pull {
				pins_cmd_dat {
					pinmux = <PINMUX_GPIO7__FUNC_GPIO7>;
					bias-pull-down;
				};
			};
gpio_goodix_clk_6mA: gpio_goodix_clk_6mA {
			pins_cmd_dat {
				pinmux = <PINMUX_GPIO28__FUNC_SPI5_CLK>;
				drive-strength = <2>;
			};
		};
gpio_goodix_mosi_6mA: gpio_goodix_mosi_6mA {
			pins_cmd_dat {
				pinmux = <PINMUX_GPIO30__FUNC_SPI5_MO>;
				drive-strength = <2>;
			};
		};
gpio_goodix_miso_6mA: gpio_goodix_miso_6mA {
			pins_cmd_dat {
				pinmux = <PINMUX_GPIO31__FUNC_SPI5_MI>;
				drive-strength = <3>;
			};
		};
gpio_goodix_cs_6mA: gpio_goodix_cs_6mA {
			pins_cmd_dat {
				pinmux = <PINMUX_GPIO29__FUNC_SPI5_CSB>;
				drive-strength = <2>;
			};
		};
gpio_goodix_cs_func: gpio_goodix_cs_func {
			pins_cmd_dat {
				pinmux = <PINMUX_GPIO29__FUNC_SPI5_CSB>;
				drive-strength = <2>;
			};
		};
};
//#endif

//#ifdef OPLUS_FEATURE_SWTP
&swtp {
    compatible = "mediatek, swtp-eint";
    debounce = <512000>;
};
//#endif  /*OPLUS_FEATURE_SWTP*/

/*End of this file, DO NOT ADD ANYTHING HERE*/

